# AM13E23219 register map
Vendor: Texas Instruments; File version: 1.0
CPU: CM33 r0p1, little endian, MPU, FPU, VTOR, 4 interrupt priority bits
Registers are 32-bit, read-write, reset 0x0 unless marked. A register's access mark holds for its fields unless they carry their own. Offsets are from the block's base; [hi:lo] are bit positions; lines under a group give offsets from that group; {n}, {i} and the like mark numbered series.

## PWMXBAR — EPWM_XBAR module
Base 0x40469000
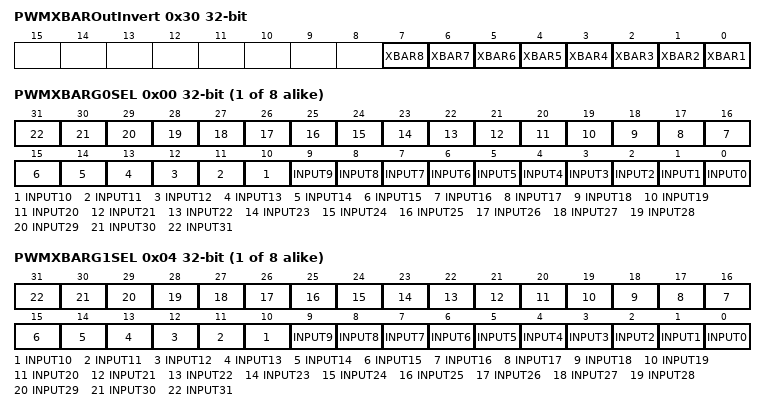
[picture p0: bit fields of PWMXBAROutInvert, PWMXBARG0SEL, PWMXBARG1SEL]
0x30 PWMXBAROutInvert — Output Signal Invert Select
  [n-1] XBAR{n} (n=1..8) — Invert XBAR Output Select for XBAR{n}
0x80 PWMXBARLock — Configuration Lock register
  [0] LOCK — Locks the configuration for EPWM-XBAR
{0x100+0x40*i} EPWM_XBAR_REGS_RegisterFile0[{i}] (i=0..7) group
  0x00 PWMXBARG0SEL — PWMXBAR G0 Input Select
    [n] INPUT{n} (n=0..31) — Select bit for INPUT{n}
  0x04 PWMXBARG1SEL — PWMXBAR G1 Input Select
    [n] INPUT{n} (n=0..31) — Select bit for INPUT{n}

## OUTPUTXBAR — OUTPUTXBAR module
Base 0x4046A000
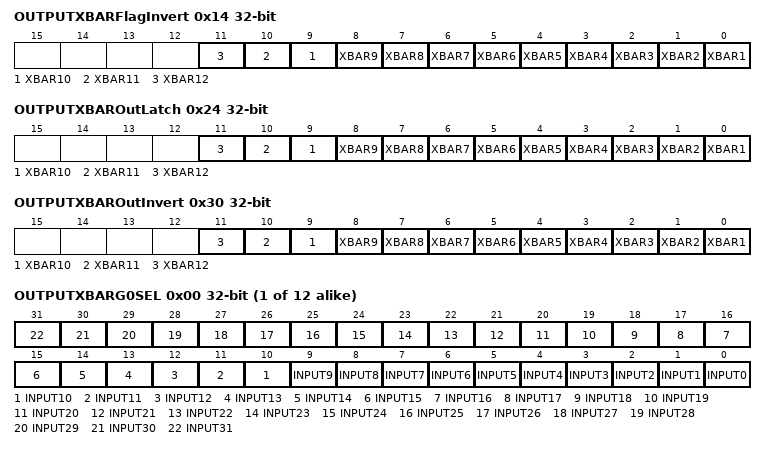
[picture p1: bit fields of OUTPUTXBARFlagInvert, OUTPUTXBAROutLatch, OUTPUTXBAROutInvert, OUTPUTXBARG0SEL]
0x14 OUTPUTXBARFlagInvert — Output Signal inversion register
  [n-1] XBAR{n} (n=1..12) — Invert XBAR Output Before Latch for XBAR{n}
0x24 OUTPUTXBAROutLatch — Output Signal Select Latch
  [n-1] XBAR{n} (n=1..12) — XBAR Output Latch Select for XBAR{n}
0x30 OUTPUTXBAROutInvert — Output Signal Invert Select
  [n-1] XBAR{n} (n=1..12) — Invert XBAR Output for XBAR{n}
0x80 OUTPUTXBARLock — Configuration Lock register
  [0] LOCK — Locks the configuration for EOUTPUT-XBAR
{0x100+0x40*i} OUTPUTXBAR_REGS_RegisterFile0[{i}] (i=0..11) group
  0x00 OUTPUTXBARG0SEL — OUTPUTXBAR G0 Input Select
    [n] INPUT{n} (n=0..31) — Select bit for INPUT{n}
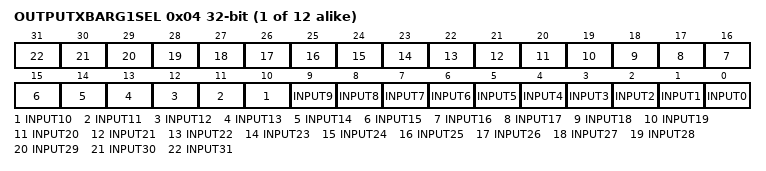
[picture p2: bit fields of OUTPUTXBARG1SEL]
  0x04 OUTPUTXBARG1SEL — OUTPUTXBAR G1 Input Select
    [n] INPUT{n} (n=0..31) — Select bit for INPUT{n}

## SYNC — SYNC_SOC module
Base 0x4046B000
0x00 SYNCSELECT — Sync Input and Output Select Register
  [28:24] SYNCOUT — Select EXT Syncout Source
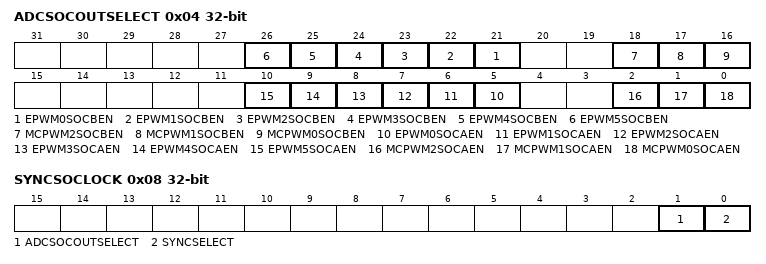
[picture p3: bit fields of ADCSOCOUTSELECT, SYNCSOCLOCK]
0x04 ADCSOCOUTSELECT — External ADCSOC Select Register
  [n+21] EPWM{n}SOCBEN (n=0..5) — EPWM{n}SOCBEN Enable for ADCSOCBOn
  [18] MCPWM2SOCBEN — MCPWM2SOCBEN Enable for ADCSOCBOn
  [17] MCPWM1SOCBEN — MCPWM1SOCBEN Enable for ADCSOCBOn
  [16] MCPWM0SOCBEN — MCPWM0SOCBEN Enable for ADCSOCBOn
  [n+5] EPWM{n}SOCAEN (n=0..5) — EPWM{n}SOCAEN Enable for ADCSOCAOn
  [2] MCPWM2SOCAEN — MCPWM2SOCAEN Enable for ADCSOCAOn
  [1] MCPWM1SOCAEN — MCPWM1SOCAEN Enable for ADCSOCAOn
  [0] MCPWM0SOCAEN — MCPWM0SOCAEN Enable for ADCSOCAOn
0x08 SYNCSOCLOCK — SYNCSEL and EXTADCSOC Select Lock register
  [1] ADCSOCOUTSELECT — ADCSOCOUTSELECT Register Lock bit
  [0] SYNCSELECT — SYNCSEL Register Lock bit

## OUTPUTXBAR0_FLAGS — OUTPUTXBAR_FLAG module
Base 0x40470000
Same registers: OUTPUTXBAR1_FLAGS 0x40471000, OUTPUTXBAR2_FLAGS 0x40472000, OUTPUTXBAR3_FLAGS 0x40473000, OUTPUTXBAR4_FLAGS 0x40474000, OUTPUTXBAR5_FLAGS 0x40475000, OUTPUTXBAR6_FLAGS 0x40476000, OUTPUTXBAR7_FLAGS 0x40477000
0x10 OUTPUTXBARStatus ro — Output Signal Status register
  [0] STS — Output Signal Status
0x18 OUTPUTXBARFlag ro — Output latched flag register
  [0] FLG — Output Signal Latched Flag Status
0x1C OUTPUTXBARFlagClear — Output latched flag clear register
  [0] FLG — Output Signal Latched Flag Clear
0x20 OUTPUTXBARFlagForce — Output latched flag Force register
  [0] FLG — Output Signal Latched Flag Force

## UNICOMM0 — UNICOMM module
Base 0x40630000
Same registers: UNICOMM1 0x40632000, UNICOMM2 0x40634000, UNICOMM3 0x40670000, UNICOMM4 0x40672000, UNICOMM5 0x40674000
0x800 GPRCM group
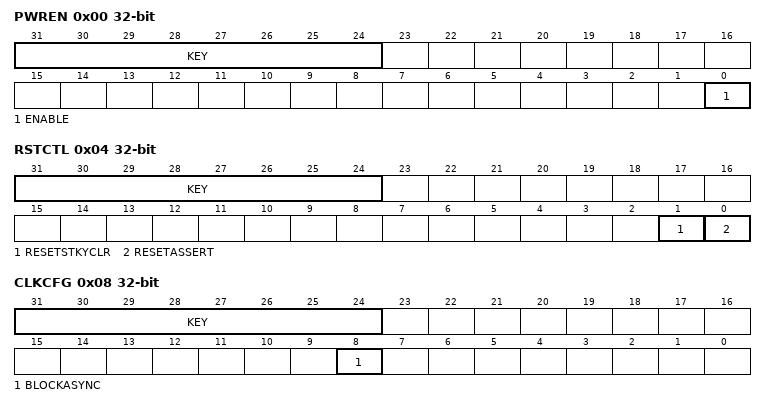
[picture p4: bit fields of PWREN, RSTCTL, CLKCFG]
  0x00 PWREN access per field — Power enable
    [31:24] KEY wo — Key which must be written for the write to take effect.
      38=KEY (Write key.)
    [0] ENABLE rw — Power Enable
      0=DISABLE (Disable Power); 1=ENABLE (Enable Power)
  0x04 RSTCTL access per field — Reset Control
    [31:24] KEY wo — Key which must be written for the write to take effect.
      177=KEY (Write key.)
    [1] RESETSTKYCLR rw — Reset sticky bit clear
      0=NOP (Writing 0 has no effect); 1=CLR (Clear reset sticky bit)
    [0] RESETASSERT rw — Reset assertion to the peripheral
      0=NOP (Writing 0 has no effect); 1=ASSERT (Assert reset)
  0x08 CLKCFG access per field — Peripheral Clock Configuration Register
    [31:24] KEY wo — Key which must be written for the write to take effect.
      169=KEY (Write key.)
    [8] BLOCKASYNC rw — Async Clock Request is blocked from starting SYSOSC or forcing bus clock to 32MHz
      0=DISABLE (Not block async clock request); 1=ENABLE (Block async clock request)
  0x14 STAT ro — Status Register
    [16] RESETSTKY — Reset sticky bit
      0=NORES (The peripheral has not been reset since this bit was last cleared by RESETSTKYCLR in the RSTCTL register); 1=RESET (The peripheral was reset since the last bit clear)
0x1100 IPMODE — Mode Selection Register
  [1:0] SELECT — Free run control
    0=UART (Default functionality is UART); 1=SPI (SPG in SPI Mode); 2=I2C_CONTROLLER (SPG in I2C Controller Mode); 3=I2C_PERIPHERAL (SPG in I2C Peripheral Mode)
